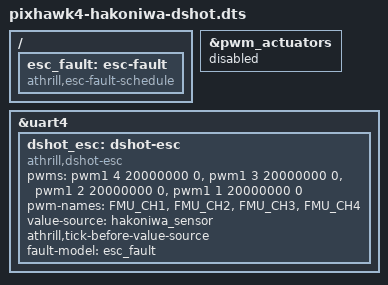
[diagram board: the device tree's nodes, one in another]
/* SPDX-License-Identifier: MIT */

/*
 * Pixhawk 4 with Hakoniwa, motors 1-4 on DShot ESCs.
 *
 * PX4 v1.17.0 drives FMU outputs 1-4 (TIM1 CH4..CH1) with DShot when
 * PWM_AUX_TIM0 is -5/-4/-3 (DShot150/300/600). The ESC decodes each motor's
 * frame and gives its throttle to the Hakoniwa sink, in place of the PWM
 * actuator map (both would set every actuator channel of the sink), and
 * answers telemetry requests with KISS frames on UART4.
 */

#include "pixhawk4-hakoniwa.dts"

&pwm_actuators {
	status = "disabled";
};

/*
 * The ESC's fault-injection point: a schedule fault model with no stop, so
 * nothing changes until a run names one with the host value
 * DEVICE_CONFIG_ESC_MOTOR_STOP ("motor@time-ms", e.g. "2@40000" stops PX4's
 * motor 3 at 40 s).
 */
/ {
	esc_fault: esc-fault {
		compatible = "athrill,esc-fault-schedule";
	};
};

/*
 * The ESC sits on UART4 (PX4 TELEM4, /dev/ttyS3): its KISS telemetry line.
 * PX4 reads it with DSHOT_TEL_CFG = 104 (TELEM 4).
 */
&uart4 {
	dshot_esc: dshot-esc {
		compatible = "athrill,dshot-esc";
		/* FMU_CH1..FMU_CH4, the motor order of PWM_AUX_FUNC1..4 */
		pwms = <&pwm1 4 20000000 0>,
		       <&pwm1 3 20000000 0>,
		       <&pwm1 2 20000000 0>,
		       <&pwm1 1 20000000 0>;
		pwm-names = "FMU_CH1", "FMU_CH2", "FMU_CH3", "FMU_CH4";
		value-source = <&hakoniwa_sensor>;
		athrill,tick-before-value-source;
		fault-model = <&esc_fault>;
	};
};
